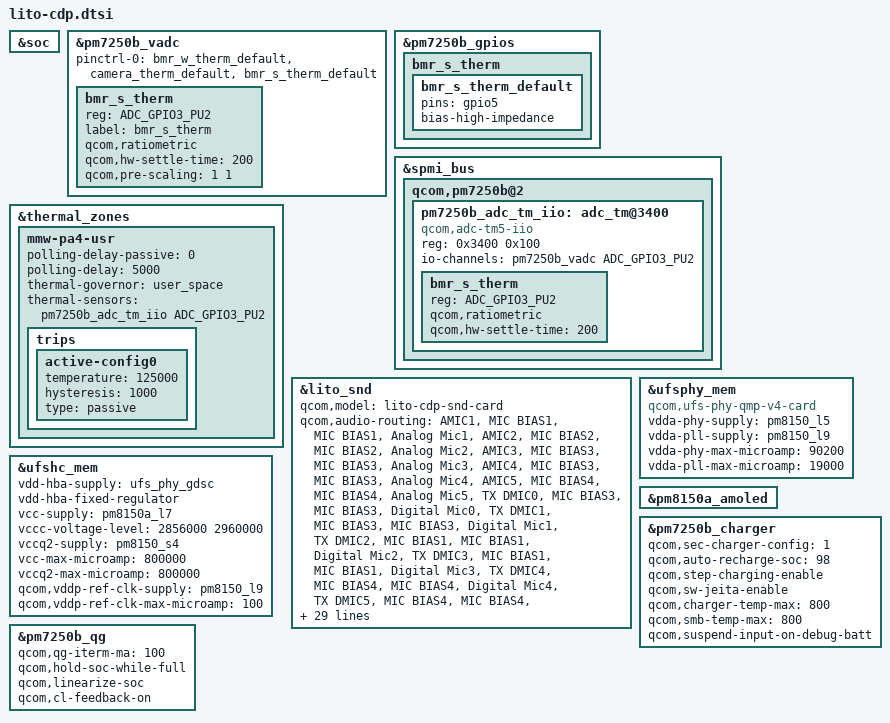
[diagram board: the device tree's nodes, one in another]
#include "lito-audio-overlay.dtsi"
#include "lito-pmic-overlay.dtsi"

&soc {

};

&pm7250b_vadc {
	pinctrl-0 = <
		&bmr_w_therm_default
		&camera_therm_default
		&bmr_s_therm_default
	>;

	bmr_s_therm {
		reg = <ADC_GPIO3_PU2>;
		label = "bmr_s_therm";
		qcom,ratiometric;
		qcom,hw-settle-time = <200>;
		qcom,pre-scaling = <1 1>;
	};
};

&pm7250b_gpios {
	bmr_s_therm {
		bmr_s_therm_default: bmr_s_therm_default {
			pins = "gpio5";
			bias-high-impedance;
		};
	};
};

&spmi_bus {
	qcom,pm7250b@2 {
		pm7250b_adc_tm_iio: adc_tm@3400 {
			compatible = "qcom,adc-tm5-iio";
			reg = <0x3400 0x100>;
			#thermal-sensor-cells = <1>;
			io-channels = <&pm7250b_vadc ADC_GPIO3_PU2>;

			bmr_s_therm {
				reg = <ADC_GPIO3_PU2>;
				qcom,ratiometric;
				qcom,hw-settle-time = <200>;
			};
		};
	};
};

&thermal_zones {
	mmw-pa4-usr {
		polling-delay-passive = <0>;
		polling-delay = <5000>;
		thermal-governor = "user_space";
		thermal-sensors = <&pm7250b_adc_tm_iio ADC_GPIO3_PU2>;
		trips {
			active-config0 {
				temperature = <125000>;
				hysteresis = <1000>;
				type = "passive";
			};
		};
	};
};

&lito_snd {
	qcom,model = "lito-cdp-snd-card";
	qcom,audio-routing =
		"AMIC1", "MIC BIAS1",
		"MIC BIAS1", "Analog Mic1",
		"AMIC2", "MIC BIAS2",
		"MIC BIAS2", "Analog Mic2",
		"AMIC3", "MIC BIAS3",
		"MIC BIAS3", "Analog Mic3",
		"AMIC4", "MIC BIAS3",
		"MIC BIAS3", "Analog Mic4",
		"AMIC5", "MIC BIAS4",
		"MIC BIAS4", "Analog Mic5",
		"TX DMIC0", "MIC BIAS3",
		"MIC BIAS3", "Digital Mic0",
		"TX DMIC1", "MIC BIAS3",
		"MIC BIAS3", "Digital Mic1",
		"TX DMIC2", "MIC BIAS1",
		"MIC BIAS1", "Digital Mic2",
		"TX DMIC3", "MIC BIAS1",
		"MIC BIAS1", "Digital Mic3",
		"TX DMIC4", "MIC BIAS4",
		"MIC BIAS4", "Digital Mic4",
		"TX DMIC5", "MIC BIAS4",
		"MIC BIAS4", "Digital Mic5",
		"IN1_HPHL", "HPHL_OUT",
		"IN2_HPHR", "HPHR_OUT",
		"IN3_AUX", "AUX_OUT",
		"TX SWR_ADC0", "ADC1_OUTPUT",
		"TX SWR_ADC1", "ADC2_OUTPUT",
		"TX SWR_ADC2", "ADC3_OUTPUT",
		"TX SWR_ADC3", "ADC4_OUTPUT",
		"TX SWR_DMIC0", "DMIC1_OUTPUT",
		"TX SWR_DMIC1", "DMIC2_OUTPUT",
		"TX SWR_DMIC2", "DMIC3_OUTPUT",
		"TX SWR_DMIC3", "DMIC4_OUTPUT",
		"TX SWR_DMIC4", "DMIC5_OUTPUT",
		"TX SWR_DMIC5", "DMIC6_OUTPUT",
		"TX SWR_DMIC6", "DMIC7_OUTPUT",
		"TX SWR_DMIC7", "DMIC8_OUTPUT",
		"WSA SRC0_INP", "SRC0",
		"WSA_TX DEC0_INP", "TX DEC0 MUX",
		"WSA_TX DEC1_INP", "TX DEC1 MUX",
		"RX_TX DEC0_INP", "TX DEC0 MUX",
		"RX_TX DEC1_INP", "TX DEC1 MUX",
		"RX_TX DEC2_INP", "TX DEC2 MUX",
		"RX_TX DEC3_INP", "TX DEC3 MUX",
		"SpkrLeft IN", "WSA_SPK1 OUT",
		"SpkrRight IN", "WSA_SPK2 OUT",
		"VA_AIF1 CAP", "VA_SWR_CLK",
		"VA_AIF2 CAP", "VA_SWR_CLK",
		"VA_AIF3 CAP", "VA_SWR_CLK",
		"VA DMIC0", "MIC BIAS3",
		"VA DMIC1", "MIC BIAS3",
		"VA DMIC2", "MIC BIAS1",
		"VA DMIC3", "MIC BIAS1",
		"VA DMIC4", "MIC BIAS4",
		"VA DMIC5", "MIC BIAS4",
		"VA SWR_ADC0", "ADC1_OUTPUT",
		"VA SWR_ADC1", "ADC2_OUTPUT",
		"VA SWR_ADC2", "ADC3_OUTPUT",
		"VA SWR_ADC3", "ADC4_OUTPUT",
		"VA SWR_MIC0", "DMIC1_OUTPUT",
		"VA SWR_MIC1", "DMIC2_OUTPUT",
		"VA SWR_MIC2", "DMIC3_OUTPUT",
		"VA SWR_MIC3", "DMIC4_OUTPUT",
		"VA SWR_MIC4", "DMIC5_OUTPUT",
		"VA SWR_MIC5", "DMIC6_OUTPUT",
		"VA SWR_MIC6", "DMIC7_OUTPUT",
		"VA SWR_MIC7", "DMIC8_OUTPUT";
};

&ufsphy_mem {
	compatible = "qcom,ufs-phy-qmp-v4-card";

	vdda-phy-supply = <&pm8150_l5>;
	vdda-pll-supply = <&pm8150_l9>;
	vdda-phy-max-microamp = <90200>;
	vdda-pll-max-microamp = <19000>;

	status = "ok";
};

&ufshc_mem {
	vdd-hba-supply = <&ufs_phy_gdsc>;
	vdd-hba-fixed-regulator;
	vcc-supply = <&pm8150a_l7>;
	vccc-voltage-level = <2856000 2960000>;
	vccq2-supply = <&pm8150_s4>;
	vcc-max-microamp = <800000>;
	vccq2-max-microamp = <800000>;

	qcom,vddp-ref-clk-supply = <&pm8150_l9>;
	qcom,vddp-ref-clk-max-microamp = <100>;

	status = "ok";
};

&pm8150a_amoled {
	status = "ok";
};

&pm7250b_charger {
	status = "ok";
	qcom,sec-charger-config = <1>;
	qcom,auto-recharge-soc = <98>;
	qcom,step-charging-enable;
	qcom,sw-jeita-enable;
	qcom,charger-temp-max = <800>;
	qcom,smb-temp-max = <800>;
	qcom,suspend-input-on-debug-batt;
};

&pm7250b_qg {
	status = "ok";
	qcom,qg-iterm-ma = <100>;
	qcom,hold-soc-while-full;
	qcom,linearize-soc;
	qcom,cl-feedback-on;
};
